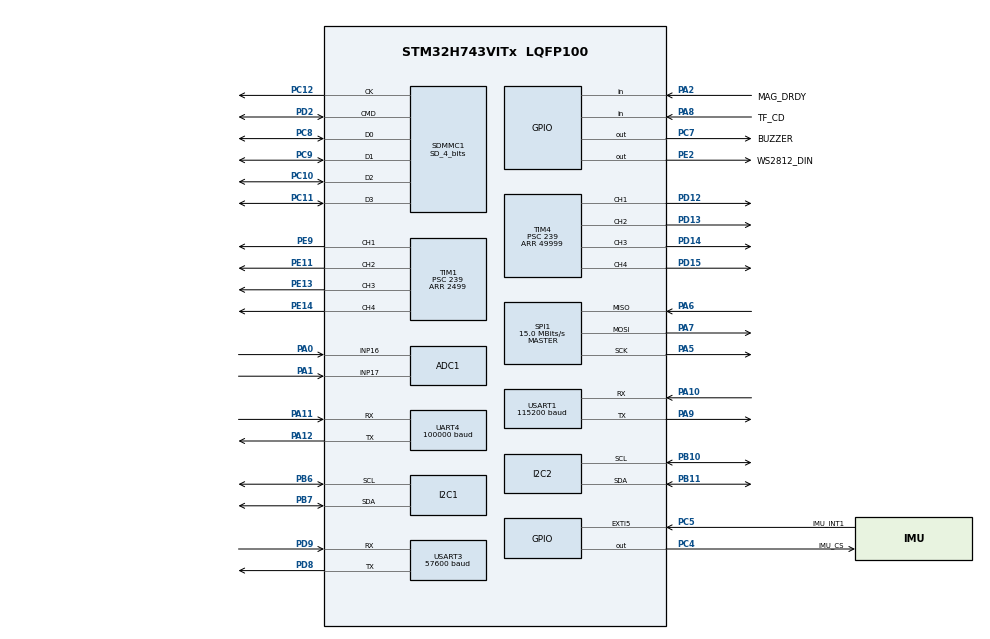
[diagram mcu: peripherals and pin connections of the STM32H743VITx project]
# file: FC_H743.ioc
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ADC1.Channel-0\#ChannelRegularConversion=ADC_CHANNEL_16
ADC1.Channel-2\#ChannelRegularConversion=ADC_CHANNEL_17
ADC1.ClockPrescaler=ADC_CLOCK_ASYNC_DIV1
ADC1.NbrOfConversion=2
ADC1.NbrOfConversionFlag=1
ADC1.OffsetNumber-0\#ChannelRegularConversion=ADC_OFFSET_NONE
ADC1.OffsetNumber-2\#ChannelRegularConversion=ADC_OFFSET_NONE
ADC1.OffsetSignedSaturation-0\#ChannelRegularConversion=DISABLE
ADC1.OffsetSignedSaturation-2\#ChannelRegularConversion=DISABLE
ADC1.Rank-0\#ChannelRegularConversion=1
ADC1.Rank-2\#ChannelRegularConversion=2
ADC1.SamplingTime-0\#ChannelRegularConversion=ADC_SAMPLETIME_64CYCLES_5
ADC1.SamplingTime-2\#ChannelRegularConversion=ADC_SAMPLETIME_64CYCLES_5
ADC1.master=1
CORTEX_M7.default_mode_Activation=1
I2C1.Timing=0x307075B1
I2C2.Timing=0x307075B1
Mcu.Family=STM32H7
Mcu.Name=STM32H743VITx
Mcu.Package=LQFP100
NVIC.EXTI9_5_IRQn=true\:0\:0\:false\:false\:true\:true\:true\:true
NVIC.PriorityGroup=NVIC_PRIORITYGROUP_4
NVIC.UART4_IRQn=true\:0\:0\:false\:false\:true\:true\:true\:true
PA0.Mode=IN16-Single-Ended
PA0.Signal=ADC1_INP16
PA1.Mode=IN17-Single-Ended
PA1.Signal=ADC1_INP17
PA10.Mode=Asynchronous
PA10.Signal=USART1_RX
PA11.Mode=Asynchronous
PA11.Signal=UART4_RX
PA12.Mode=Asynchronous
PA12.Signal=UART4_TX
PA13\ (JTMS/SWDIO).Mode=Serial_Wire
PA13\ (JTMS/SWDIO).Signal=DEBUG_JTMS-SWDIO
PA14\ (JTCK/SWCLK).Mode=Serial_Wire
PA14\ (JTCK/SWCLK).Signal=DEBUG_JTCK-SWCLK
PA2.GPIO_Label=MAG_DRDY
PA2.Signal=GPIO_Input
PA5.Mode=Full_Duplex_Master
PA5.Signal=SPI1_SCK
PA6.Mode=Full_Duplex_Master
PA6.Signal=SPI1_MISO
PA7.Mode=Full_Duplex_Master
PA7.Signal=SPI1_MOSI
PA8.GPIO_Label=TF_CD
PA8.Signal=GPIO_Input
PA9.Mode=Asynchronous
PA9.Signal=USART1_TX
PB10.Mode=I2C
PB10.Signal=I2C2_SCL
PB11.Mode=I2C
PB11.Signal=I2C2_SDA
PB6.Mode=I2C
PB6.Signal=I2C1_SCL
PB7.Mode=I2C
PB7.Signal=I2C1_SDA
PC10.Mode=SD_4_bits_Wide_bus
PC10.Signal=SDMMC1_D2
PC11.Mode=SD_4_bits_Wide_bus
PC11.Signal=SDMMC1_D3
PC12.Mode=SD_4_bits_Wide_bus
PC12.Signal=SDMMC1_CK
PC4.GPIO_Label=IMU_CS
PC4.PinState=GPIO_PIN_SET
PC4.Signal=GPIO_Output
PC5.GPIO_Label=IMU_INT1
PC5.GPIO_ModeDefaultEXTI=GPIO_MODE_IT_RISING
PC5.Signal=GPXTI5
PC7.GPIO_Label=BUZZER
PC7.Signal=GPIO_Output
PC8.Mode=SD_4_bits_Wide_bus
PC8.Signal=SDMMC1_D0
PC9.Mode=SD_4_bits_Wide_bus
PC9.Signal=SDMMC1_D1
PD12.Signal=S_TIM4_CH1
PD13.Signal=S_TIM4_CH2
PD14.Signal=S_TIM4_CH3
PD15.Signal=S_TIM4_CH4
PD2.Mode=SD_4_bits_Wide_bus
PD2.Signal=SDMMC1_CMD
PD8.Mode=Asynchronous
PD8.Signal=USART3_TX
PD9.Mode=Asynchronous
PD9.Signal=USART3_RX
PE11.Signal=S_TIM1_CH2
PE13.Signal=S_TIM1_CH3
PE14.Signal=S_TIM1_CH4
PE2.GPIO_Label=WS2812_DIN
PE2.Signal=GPIO_Output
PE9.Signal=S_TIM1_CH1
PH0-OSC_IN\ (PH0).Mode=HSE-External-Oscillator
PH0-OSC_IN\ (PH0).Signal=RCC_OSC_IN
PH1-OSC_OUT\ (PH1).Mode=HSE-External-Oscillator
PH1-OSC_OUT\ (PH1).Signal=RCC_OSC_OUT
ProjectManager.HeapSize=0x200
ProjectManager.StackSize=0x400
ProjectManager.TargetToolchain=CMake
RCC.ADCFreq_Value=30000000
RCC.APB1Freq_Value=120000000
RCC.APB2Freq_Value=120000000
RCC.APB3Freq_Value=120000000
RCC.APB4Freq_Value=120000000
RCC.CortexFreq_Value=480000000
RCC.D1PPRE=RCC_APB3_DIV2
RCC.D2PPRE1=RCC_APB1_DIV2
RCC.D2PPRE2=RCC_APB2_DIV2
RCC.D3PPRE=RCC_APB4_DIV2
RCC.DIVM1=5
RCC.DIVM2=5
RCC.DIVN1=192
RCC.DIVN2=96
RCC.DIVP2=16
RCC.DIVQ1=8
RCC.DIVR2=10
RCC.EnableHSEDSI-ClockTree=true
RCC.EnableLSERTC-ClockTree=true
RCC.FMCEnable-ClockTree=true
RCC.HCLKFreq_Value=240000000
RCC.HPRE=RCC_HCLK_DIV2
RCC.HSE_VALUE=25000000
RCC.I2C123CLockSelection=RCC_I2C123CLKSOURCE_D2PCLK1
RCC.PLL1_VCO_SEL-AdvancedSettings=RCC_PLL1VCOMEDIUM
RCC.PLL2FRACN=0
RCC.PLL2_VCI_Range-AdvancedSettings=RCC_PLL2VCIRANGE_3
RCC.PLL3FRACN=0
RCC.PLLFRACN=0
RCC.PLLSourceVirtual=RCC_PLLSOURCE_HSE
RCC.PWR_Regulator_Voltage_Scale=PWR_REGULATOR_VOLTAGE_SCALE0
RCC.SDMMC1CLockSelection=RCC_SDMMCCLKSOURCE_PLL
RCC.SPI123CLockSelection=RCC_SPI123CLKSOURCE_PLL
RCC.SYSCLKFreq_VALUE=480000000
RCC.SYSCLKSource=RCC_SYSCLKSOURCE_PLLCLK
RCC.SupplySource=PWR_LDO_SUPPLY
RCC.USBFreq_Value=120000000
SDMMC1.ClockDiv=4
SDMMC1.Mode=SD_4_bits
SH.S_TIM1_CH1.0=TIM1_CH1,PWM Generation1 CH1
SH.S_TIM1_CH2.0=TIM1_CH2,PWM Generation2 CH2
SH.S_TIM1_CH3.0=TIM1_CH3,PWM Generation3 CH3
SH.S_TIM1_CH4.0=TIM1_CH4,PWM Generation4 CH4
SH.S_TIM4_CH1.0=TIM4_CH1,PWM Generation1 CH1
SH.S_TIM4_CH2.0=TIM4_CH2,PWM Generation2 CH2
SH.S_TIM4_CH3.0=TIM4_CH3,PWM Generation3 CH3
SH.S_TIM4_CH4.0=TIM4_CH4,PWM Generation4 CH4
SPI1.BaudRatePrescaler=SPI_BAUDRATEPRESCALER_8
SPI1.CalculateBaudRate=15.0 MBits/s
SPI1.Direction=SPI_DIRECTION_2LINES
SPI1.Mode=SPI_MODE_MASTER
SPI1.VirtualType=VM_MASTER
TIM1.Channel-PWM\ Generation1\ CH1=TIM_CHANNEL_1
TIM1.Channel-PWM\ Generation2\ CH2=TIM_CHANNEL_2
TIM1.Channel-PWM\ Generation3\ CH3=TIM_CHANNEL_3
TIM1.Period=2499
TIM1.Prescaler=239
TIM1.Pulse-Output\ Compare4\ CH4=1500
TIM1.Pulse-PWM\ Generation1\ CH1=1500
TIM1.Pulse-PWM\ Generation2\ CH2=1500
TIM1.Pulse-PWM\ Generation3\ CH3=1500
TIM4.Channel-PWM\ Generation1\ CH1=TIM_CHANNEL_1
TIM4.Channel-PWM\ Generation2\ CH2=TIM_CHANNEL_2
TIM4.Channel-PWM\ Generation3\ CH3=TIM_CHANNEL_3
TIM4.Channel-PWM\ Generation4\ CH4=TIM_CHANNEL_4
TIM4.Period=49999
TIM4.Prescaler=239
TIM4.Pulse-PWM\ Generation1\ CH1=1500
TIM4.Pulse-PWM\ Generation2\ CH2=1500
TIM4.Pulse-PWM\ Generation3\ CH3=1500
TIM4.Pulse-PWM\ Generation4\ CH4=1500
UART4.BaudRate=100000
UART4.RxPinLevelInvertParam=UART_ADVFEATURE_RXINV_ENABLE
UART4.StopBits=UART_STOPBITS_2
UART4.VirtualMode-Asynchronous=VM_ASYNC
USART1.BaudRate=115200
USART1.VirtualMode-Asynchronous=VM_ASYNC
USART3.BaudRate=57600
USART3.VirtualMode-Asynchronous=VM_ASYNC
VP_MEMORYMAP_VS_MEMORYMAP.Mode=CurAppReg
VP_TIM1_VS_ClockSourceINT.Mode=Internal
VP_TIM4_VS_ClockSourceINT.Mode=Internal
board=custom

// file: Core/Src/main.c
/* USER CODE BEGIN Header */
/**
  ******************************************************************************
  * @file           : main.c
  * @brief          : Main program body
  ******************************************************************************
  * @attention
  *
  * Copyright (c) 2026 STMicroelectronics.
  * All rights reserved.
  *
  * This software is licensed under terms that can be found in the LICENSE file
  * in the root directory of this software component.
  * If no LICENSE file comes with this software, it is provided AS-IS.
  *
  ******************************************************************************
  */
/* USER CODE END Header */
#include "main.h"
#include "adc.h"
#include "i2c.h"
#include "sdmmc.h"
#include "spi.h"
#include "tim.h"
#include "usart.h"
#include "gpio.h"

/* USER CODE BEGIN Includes */
#include "fc/fc_app.h"
/* USER CODE END Includes */

void SystemClock_Config(void);
static void MPU_Config(void);

int main(void)
{

  /* MPU Configuration--------------------------------------------------------*/
  MPU_Config();

  /* MCU Configuration--------------------------------------------------------*/

  /* Reset of all peripherals, Initializes the Flash interface and the Systick. */
  HAL_Init();

  /* Configure the system clock */
  SystemClock_Config();

  /* Initialize all configured peripherals */
  MX_GPIO_Init();
  MX_I2C1_Init();
  MX_I2C2_Init();
  MX_SPI1_Init();
  MX_SDMMC1_SD_Init();
  MX_USART1_UART_Init();
  MX_USART3_UART_Init();
  MX_UART4_Init();
  MX_ADC1_Init();
  MX_TIM1_Init();
  MX_TIM4_Init();
  /* USER CODE BEGIN 2 */
  FC_Init();
  /* USER CODE END 2 */

  /* Infinite loop */
  while (1)
  {

    /* USER CODE BEGIN 3 */
    FC_Loop();
  }
  /* USER CODE END 3 */
}

void SystemClock_Config(void)
{
  RCC_OscInitTypeDef RCC_OscInitStruct = {0};
  RCC_ClkInitTypeDef RCC_ClkInitStruct = {0};

  /** Supply configuration update enable
  */
  HAL_PWREx_ConfigSupply(PWR_LDO_SUPPLY);

  /** Configure the main internal regulator output voltage
  */
  __HAL_PWR_VOLTAGESCALING_CONFIG(PWR_REGULATOR_VOLTAGE_SCALE0);

  while(!__HAL_PWR_GET_FLAG(PWR_FLAG_VOSRDY)) {}

  /** Initializes the RCC Oscillators according to the specified parameters
  * in the RCC_OscInitTypeDef structure.
  */
  RCC_OscInitStruct.OscillatorType = RCC_OSCILLATORTYPE_HSE;
  RCC_OscInitStruct.HSEState = RCC_HSE_ON;
  RCC_OscInitStruct.PLL.PLLState = RCC_PLL_ON;
  RCC_OscInitStruct.PLL.PLLSource = RCC_PLLSOURCE_HSE;
  RCC_OscInitStruct.PLL.PLLM = 5;
  RCC_OscInitStruct.PLL.PLLN = 192;
  RCC_OscInitStruct.PLL.PLLP = 2;
  RCC_OscInitStruct.PLL.PLLQ = 8;
  RCC_OscInitStruct.PLL.PLLR = 2;
  RCC_OscInitStruct.PLL.PLLRGE = RCC_PLL1VCIRANGE_2;
  RCC_OscInitStruct.PLL.PLLVCOSEL = RCC_PLL1VCOWIDE;
  RCC_OscInitStruct.PLL.PLLFRACN = 0;
  if (HAL_RCC_OscConfig(&RCC_OscInitStruct) != HAL_OK)
  {
    Error_Handler();
  }

  /** Initializes the CPU, AHB and APB buses clocks
  */
  RCC_ClkInitStruct.ClockType = RCC_CLOCKTYPE_HCLK|RCC_CLOCKTYPE_SYSCLK
                              |RCC_CLOCKTYPE_PCLK1|RCC_CLOCKTYPE_PCLK2
                              |RCC_CLOCKTYPE_D3PCLK1|RCC_CLOCKTYPE_D1PCLK1;
  RCC_ClkInitStruct.SYSCLKSource = RCC_SYSCLKSOURCE_PLLCLK;
  RCC_ClkInitStruct.SYSCLKDivider = RCC_SYSCLK_DIV1;
  RCC_ClkInitStruct.AHBCLKDivider = RCC_HCLK_DIV2;
  RCC_ClkInitStruct.APB3CLKDivider = RCC_APB3_DIV2;
  RCC_ClkInitStruct.APB1CLKDivider = RCC_APB1_DIV2;
  RCC_ClkInitStruct.APB2CLKDivider = RCC_APB2_DIV2;
  RCC_ClkInitStruct.APB4CLKDivider = RCC_APB4_DIV2;

  if (HAL_RCC_ClockConfig(&RCC_ClkInitStruct, FLASH_LATENCY_4) != HAL_OK)
  {
    Error_Handler();
  }
}

 /* MPU Configuration */

void MPU_Config(void)
{
  MPU_Region_InitTypeDef MPU_InitStruct = {0};

  /* Disables the MPU */
  HAL_MPU_Disable();

  /** Initializes and configures the Region and the memory to be protected
  */
  MPU_InitStruct.Enable = MPU_REGION_ENABLE;
  MPU_InitStruct.Number = MPU_REGION_NUMBER0;
  MPU_InitStruct.BaseAddress = 0x0;
  MPU_InitStruct.Size = MPU_REGION_SIZE_4GB;
  MPU_InitStruct.SubRegionDisable = 0x87;
  MPU_InitStruct.TypeExtField = MPU_TEX_LEVEL0;
  MPU_InitStruct.AccessPermission = MPU_REGION_NO_ACCESS;
  MPU_InitStruct.DisableExec = MPU_INSTRUCTION_ACCESS_DISABLE;
  MPU_InitStruct.IsShareable = MPU_ACCESS_SHAREABLE;
  MPU_InitStruct.IsCacheable = MPU_ACCESS_NOT_CACHEABLE;
  MPU_InitStruct.IsBufferable = MPU_ACCESS_NOT_BUFFERABLE;

  HAL_MPU_ConfigRegion(&MPU_InitStruct);
  /* Enables the MPU */
  HAL_MPU_Enable(MPU_PRIVILEGED_DEFAULT);

}

void Error_Handler(void)
{
  __disable_irq();
  while (1)
  {
  }
}
